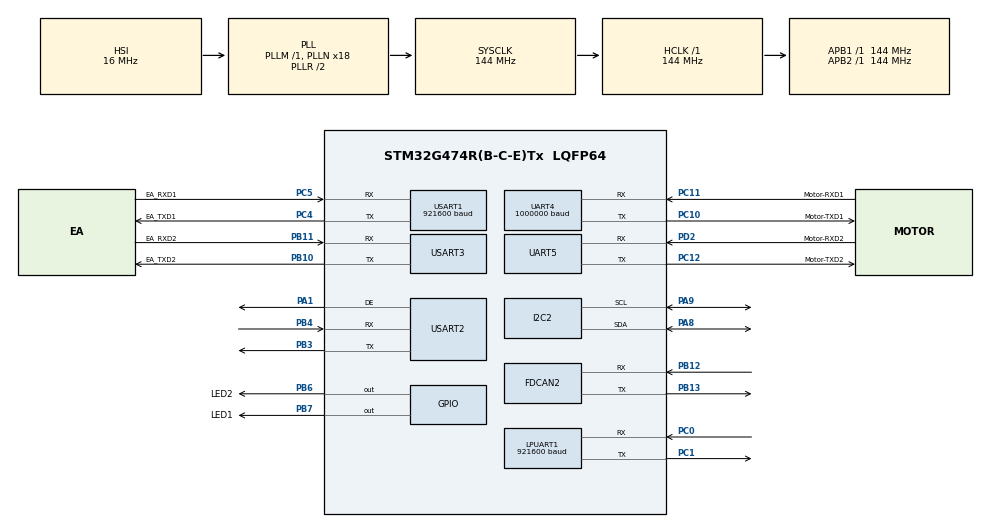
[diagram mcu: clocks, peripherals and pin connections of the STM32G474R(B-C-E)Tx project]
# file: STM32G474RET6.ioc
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FDCAN2.CalculateBaudRateNominal=2999999
FDCAN2.CalculateTimeBitNominal=333
FDCAN2.CalculateTimeQuantumNominal=111.11111111111111
I2C2.Timing=0x60715075
LPUART1.BaudRate=921600
Mcu.Family=STM32G4
Mcu.Name=STM32G474R(B-C-E)Tx
Mcu.Package=LQFP64
NVIC.PriorityGroup=NVIC_PRIORITYGROUP_4
NVIC.TIM2_IRQn=true\:0\:0\:false\:false\:true\:true\:true\:true
NVIC.TIM3_IRQn=true\:0\:0\:false\:false\:true\:true\:true\:true
NVIC.TIM6_DAC_IRQn=true\:0\:0\:false\:false\:true\:true\:true\:true
NVIC.TIM7_DAC_IRQn=true\:0\:0\:false\:false\:true\:true\:true\:true
NVIC.USART1_IRQn=true\:0\:0\:false\:false\:true\:true\:true\:true
NVIC.USART2_IRQn=true\:0\:0\:false\:false\:true\:true\:true\:true
PA1.Mode=Hardware Flow Control (RS485)
PA1.Signal=USART2_DE
PA13.Mode=Serial_Wire
PA13.Signal=SYS_JTMS-SWDIO
PA14.Mode=Serial_Wire
PA14.Signal=SYS_JTCK-SWCLK
PA8.GPIO_Pu=GPIO_PULLUP
PA8.GPIO_Speed=GPIO_SPEED_FREQ_HIGH
PA8.Mode=I2C
PA8.Signal=I2C2_SDA
PA9.GPIO_Pu=GPIO_PULLUP
PA9.GPIO_Speed=GPIO_SPEED_FREQ_HIGH
PA9.Mode=I2C
PA9.Signal=I2C2_SCL
PB10.GPIO_Label=EA_TXD2
PB10.Mode=Asynchronous
PB10.Signal=USART3_TX
PB11.GPIO_Label=EA_RXD2
PB11.Mode=Asynchronous
PB11.Signal=USART3_RX
PB12.Mode=FDCAN_Activate
PB12.Signal=FDCAN2_RX
PB13.Mode=FDCAN_Activate
PB13.Signal=FDCAN2_TX
PB3.Mode=Asynchronous
PB3.Signal=USART2_TX
PB4.Mode=Asynchronous
PB4.Signal=USART2_RX
PB6.GPIO_Label=LED2
PB6.GPIO_PuPd=GPIO_PULLUP
PB6.GPIO_Speed=GPIO_SPEED_FREQ_HIGH
PB6.PinState=GPIO_PIN_SET
PB6.Signal=GPIO_Output
PB7.GPIO_Label=LED1
PB7.GPIO_PuPd=GPIO_PULLUP
PB7.GPIO_Speed=GPIO_SPEED_FREQ_HIGH
PB7.PinState=GPIO_PIN_SET
PB7.Signal=GPIO_Output
PC0.Mode=Asynchronous
PC0.Signal=LPUART1_RX
PC1.Mode=Asynchronous
PC1.Signal=LPUART1_TX
PC10.GPIO_Label=Motor-TXD1
PC10.Mode=Asynchronous
PC10.Signal=UART4_TX
PC11.GPIO_Label=Motor-RXD1
PC11.Mode=Asynchronous
PC11.Signal=UART4_RX
PC12.GPIO_Label=Motor-TXD2
PC12.Mode=Asynchronous
PC12.Signal=UART5_TX
PC14-OSC32_IN.Mode=LSE-External-Oscillator
PC14-OSC32_IN.Signal=RCC_OSC32_IN
PC15-OSC32_OUT.Mode=LSE-External-Oscillator
PC15-OSC32_OUT.Signal=RCC_OSC32_OUT
PC4.GPIO_Label=EA_TXD1
PC4.Mode=Asynchronous
PC4.Signal=USART1_TX
PC5.GPIO_Label=EA_RXD1
PC5.Mode=Asynchronous
PC5.Signal=USART1_RX
PD2.GPIO_Label=Motor-RXD2
PD2.Mode=Asynchronous
PD2.Signal=UART5_RX
PF0-OSC_IN.Mode=HSE-External-Oscillator
PF0-OSC_IN.Signal=RCC_OSC_IN
PF1-OSC_OUT.Mode=HSE-External-Oscillator
PF1-OSC_OUT.Signal=RCC_OSC_OUT
ProjectManager.HeapSize=0x200
ProjectManager.StackSize=0x400
ProjectManager.TargetToolchain=MDK-ARM V5.32
RCC.ADC12Freq_Value=144000000
RCC.ADC345Freq_Value=144000000
RCC.AHBFreq_Value=144000000
RCC.APB1Freq_Value=144000000
RCC.APB1TimFreq_Value=144000000
RCC.APB2Freq_Value=144000000
RCC.APB2TimFreq_Value=144000000
RCC.CortexFreq_Value=144000000
RCC.EXTERNAL_CLOCK_VALUE=12288000
RCC.HCLKFreq_Value=144000000
RCC.HSE_VALUE=8000000
RCC.HSI48_VALUE=48000000
RCC.HSI_VALUE=16000000
RCC.PLLN=18
RCC.SYSCLKFreq_VALUE=144000000
RCC.SYSCLKSource=RCC_SYSCLKSOURCE_PLLCLK
RCC.USBFreq_Value=144000000
RCC.VCOOutputFreq_Value=288000000
TIM2.PeriodNoDither=9999-1
TIM2.Prescaler=1440-1
TIM3.Prescaler=14400-1
TIM6.PeriodNoDither=99
TIM6.Prescaler=1440-1
TIM7.PeriodNoDither=99
TIM7.Prescaler=1440-1
UART4.BaudRate=1000000
USART1.BaudRate=921600
USART1.VirtualMode-Asynchronous=VM_ASYNC
USART2.VirtualMode-Asynchronous=VM_ASYNC
USART2.VirtualMode-Hardware\ Flow\ Control\ (RS485)=VM_ASYNC
USART3.VirtualMode-Asynchronous=VM_ASYNC
VP_SYS_VS_DBSignals.Mode=DisableDeadBatterySignals
VP_TIM2_VS_ClockSourceINT.Mode=Internal
VP_TIM3_VS_ClockSourceINT.Mode=Internal
VP_TIM6_VS_ClockSourceINT.Mode=Enable_Timer
VP_TIM7_VS_ClockSourceINT.Mode=Enable_Timer
board=custom

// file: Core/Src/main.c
/* USER CODE BEGIN Header */
/**
  ******************************************************************************
  * @file           : main.c
  * @brief          : Main program body
  ******************************************************************************
  * @attention
  *
  * Copyright (c) 2025 STMicroelectronics.
  * All rights reserved.
  *
  * This software is licensed under terms that can be found in the LICENSE file
  * in the root directory of this software component.
  * If no LICENSE file comes with this software, it is provided AS-IS.
  *
  ******************************************************************************
  */
/* USER CODE END Header */
#include "main.h"
#include "fdcan.h"
#include "i2c.h"
#include "usart.h"
#include "tim.h"
#include "gpio.h"

/* USER CODE BEGIN Includes */
#include "stdio.h"

#include "MODBUS_SLAVE.h"
#include "sensor_i2c.h"
/* USER CODE END Includes */

/* USER CODE BEGIN PD */
uint8_t tick10ms = 0;  // ��ʱ��ÿ10ms��1����ѭ��������
/* USER CODE END PD */

void SystemClock_Config(void);

int main(void)
{

  /* MCU Configuration--------------------------------------------------------*/

  /* Reset of all peripherals, Initializes the Flash interface and the Systick. */
  HAL_Init();

  /* Configure the system clock */
  SystemClock_Config();

  /* Initialize all configured peripherals */
  MX_GPIO_Init();
  MX_LPUART1_UART_Init();
  MX_UART4_Init();
  MX_UART5_Init();
  MX_USART1_UART_Init();
  MX_USART2_UART_Init();
  MX_USART3_UART_Init();
  MX_FDCAN2_Init();
  MX_TIM3_Init();
  MX_I2C2_Init();
  MX_TIM2_Init();
  MX_TIM6_Init();
  MX_TIM7_Init();
  /* USER CODE BEGIN 2 */
  HAL_Delay(1000);
  HAL_TIM_Base_Start_IT(&htim3);
  HAL_TIM_Base_Start_IT(&htim2);
  HAL_TIM_Base_Start_IT(&htim6);
  system.Per_Init();
  /* USER CODE END 2 */

  /* Infinite loop */
  /* USER CODE BEGIN WHILE */
  while (1)
  {
//	  HAL_UART_Transmit(&hlpuart1, (uint8_t*)"1234", 4, 100);
	//  HAL_Delay(5000);
//		ReceiveOneSensor_Print();
		//HAL_Delay(1000);

		/*
		if (tick10ms) {
        tick10ms = 0;
      ReceiveOneSensor();  // �����еĺ�������ѯ 0x0A~0x0E �� printf

    }*/

     system.System_Run();
    /* USER CODE END WHILE */

  }
}

void SystemClock_Config(void)
{
  RCC_OscInitTypeDef RCC_OscInitStruct = {0};
  RCC_ClkInitTypeDef RCC_ClkInitStruct = {0};

  /** Configure the main internal regulator output voltage
  */
  HAL_PWREx_ControlVoltageScaling(PWR_REGULATOR_VOLTAGE_SCALE1);

  /** Initializes the RCC Oscillators according to the specified parameters
  * in the RCC_OscInitTypeDef structure.
  */
  RCC_OscInitStruct.OscillatorType = RCC_OSCILLATORTYPE_HSI;
  RCC_OscInitStruct.HSIState = RCC_HSI_ON;
  RCC_OscInitStruct.HSICalibrationValue = RCC_HSICALIBRATION_DEFAULT;
  RCC_OscInitStruct.PLL.PLLState = RCC_PLL_ON;
  RCC_OscInitStruct.PLL.PLLSource = RCC_PLLSOURCE_HSI;
  RCC_OscInitStruct.PLL.PLLM = RCC_PLLM_DIV1;
  RCC_OscInitStruct.PLL.PLLN = 18;
  RCC_OscInitStruct.PLL.PLLP = RCC_PLLP_DIV2;
  RCC_OscInitStruct.PLL.PLLQ = RCC_PLLQ_DIV2;
  RCC_OscInitStruct.PLL.PLLR = RCC_PLLR_DIV2;
  if (HAL_RCC_OscConfig(&RCC_OscInitStruct) != HAL_OK)
  {
    Error_Handler();
  }

  /** Initializes the CPU, AHB and APB buses clocks
  */
  RCC_ClkInitStruct.ClockType = RCC_CLOCKTYPE_HCLK|RCC_CLOCKTYPE_SYSCLK
                              |RCC_CLOCKTYPE_PCLK1|RCC_CLOCKTYPE_PCLK2;
  RCC_ClkInitStruct.SYSCLKSource = RCC_SYSCLKSOURCE_PLLCLK;
  RCC_ClkInitStruct.AHBCLKDivider = RCC_SYSCLK_DIV1;
  RCC_ClkInitStruct.APB1CLKDivider = RCC_HCLK_DIV1;
  RCC_ClkInitStruct.APB2CLKDivider = RCC_HCLK_DIV1;

  if (HAL_RCC_ClockConfig(&RCC_ClkInitStruct, FLASH_LATENCY_4) != HAL_OK)
  {
    Error_Handler();
  }
}

void Error_Handler(void)
{
  __disable_irq();
  while (1)
  {
  }
}
